VERSION ""

NS_ :

BS_:

BU_: XXX

BO_ 85 CID_QWMLCN: 8 XXX
 SG_ sig_wotptn : 40|1@1+ (1,0) [0|1] "" XXX
 SG_ sig_twcvod : 56|8@1+ (1,0) [0|255] "" XXX

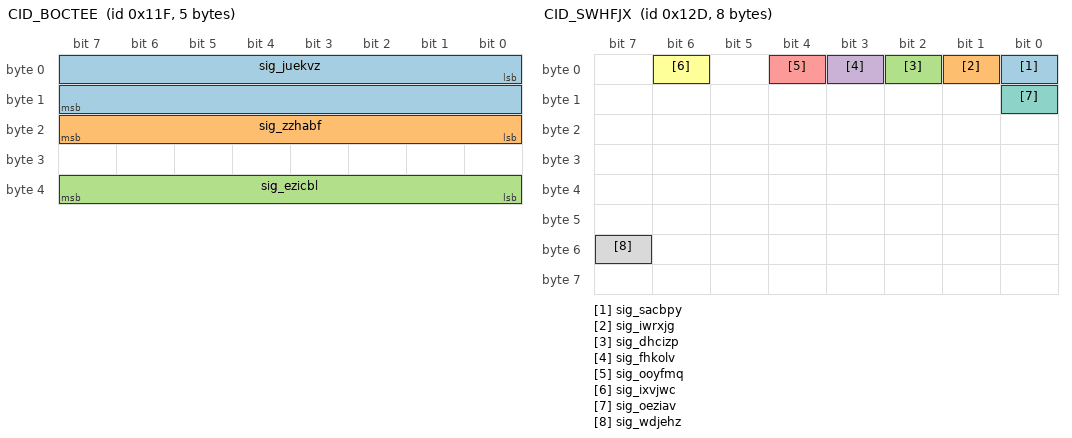
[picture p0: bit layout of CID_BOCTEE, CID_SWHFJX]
BO_ 287 CID_BOCTEE: 5 XXX
 SG_ sig_juekvz : 0|16@1- (0.1,0) [-450|450] "" XXX
 SG_ sig_zzhabf : 16|8@1+ (4,0) [0|1020] "" XXX
 SG_ sig_ezicbl : 32|8@1+ (1,0) [0|255] "" XXX

BO_ 289 CID_AZITHL: 8 XXX
 SG_ sig_vuvkgr : 0|12@1+ (1,0) [0|255] "" XXX

BO_ 301 CID_SWHFJX: 8 XXX
 SG_ sig_sacbpy : 0|1@0+ (1,0) [0|1] "" XXX
 SG_ sig_iwrxjg : 1|1@0+ (1,0) [0|1] "" XXX
 SG_ sig_dhcizp : 2|1@0+ (1,0) [0|1] "" XXX
 SG_ sig_fhkolv : 3|1@0+ (1,0) [0|1] "" XXX
 SG_ sig_ooyfmq : 4|1@0+ (1,0) [0|1] "" XXX
 SG_ sig_ixvjwc : 6|1@0+ (1,0) [0|1] "" XXX
 SG_ sig_oeziav : 8|1@0+ (1,0) [0|1] "" XXX
 SG_ sig_wdjehz : 55|1@0+ (1,0) [0|1] "" XXX

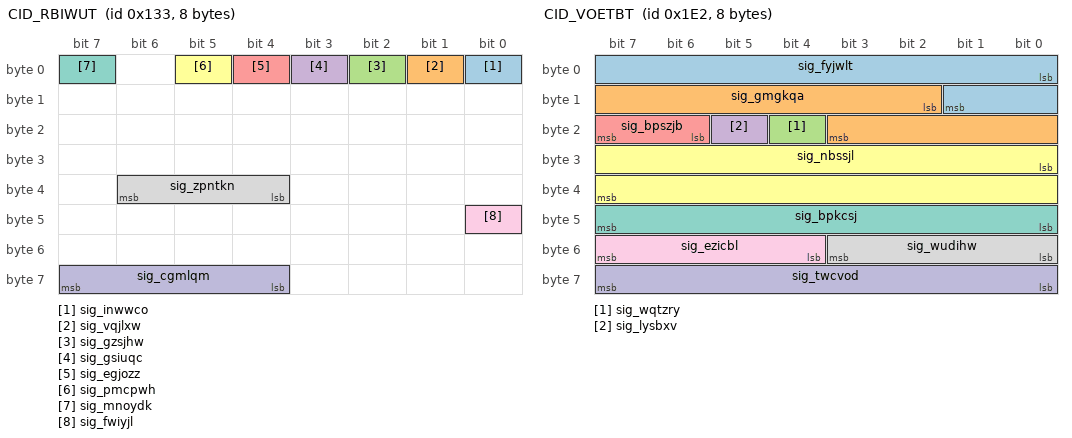
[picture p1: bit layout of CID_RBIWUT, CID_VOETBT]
BO_ 307 CID_RBIWUT: 8 XXX
 SG_ sig_inwwco : 0|1@0+ (1,0) [0|1] "" XXX
 SG_ sig_vqjlxw : 1|1@1+ (1,0) [0|1] "" XXX
 SG_ sig_gzsjhw : 2|1@1+ (1,0) [0|1] "" XXX
 SG_ sig_gsiuqc : 3|1@1+ (1,0) [0|1] "" XXX
 SG_ sig_egjozz : 4|1@0+ (1,0) [0|1] "" XXX
 SG_ sig_pmcpwh : 5|1@0+ (1,0) [0|1] "" XXX
 SG_ sig_mnoydk : 7|1@0+ (1,0) [0|1] "" XXX
 SG_ sig_zpntkn : 36|3@1+ (1,0) [0|7] "" XXX
 SG_ sig_fwiyjl : 40|1@0+ (1,0) [0|1] "" XXX
 SG_ sig_cgmlqm : 63|4@0+ (1,0) [0|15] "" XXX

BO_ 482 CID_VOETBT: 8 XXX
 SG_ sig_fyjwlt : 0|10@1- (0.01,0) [0|5] "" XXX
 SG_ sig_gmgkqa : 10|10@1- (0.01,0) [-5|0] "" XXX
 SG_ sig_wqtzry : 20|1@0+ (1,0) [0|1] "" XXX
 SG_ sig_lysbxv : 21|1@0+ (1,0) [0|1] "" XXX
 SG_ sig_bpszjb : 22|2@1+ (1,0) [0|1] "" XXX
 SG_ sig_nbssjl : 24|16@1- (0.1,0) [-780|779.9] "" XXX
 SG_ sig_bpkcsj : 47|8@0+ (1,0) [0|255] "" XXX
 SG_ sig_wudihw : 48|4@1+ (1,0) [0|15] "" XXX
 SG_ sig_ezicbl : 52|4@1+ (1,0) [0|15] "" XXX
 SG_ sig_twcvod : 56|8@1+ (1,0) [0|255] "" XXX

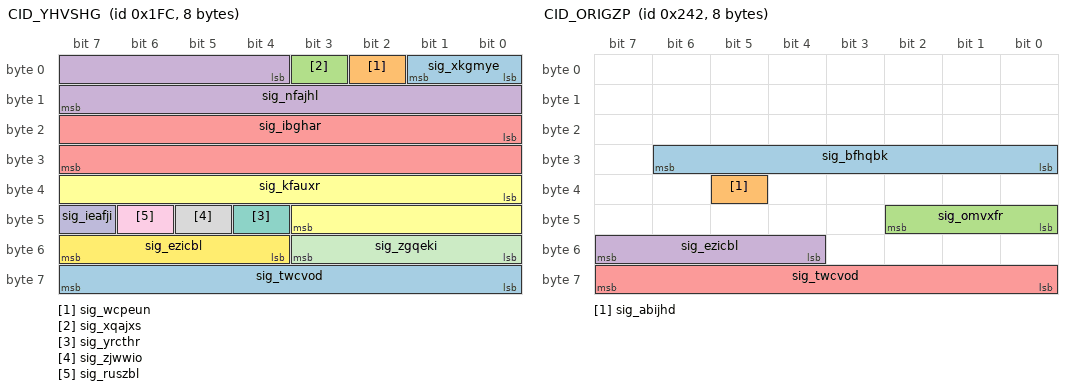
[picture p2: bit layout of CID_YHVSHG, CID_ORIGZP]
BO_ 508 CID_YHVSHG: 8 XXX
 SG_ sig_xkgmye : 0|2@1+ (1,0) [0|1] "" XXX
 SG_ sig_wcpeun : 2|1@1+ (1,0) [0|1] "" XXX
 SG_ sig_xqajxs : 3|1@0+ (1,0) [0|1] "" XXX
 SG_ sig_nfajhl : 4|12@1- (1,0) [-2048|2047] "" XXX
 SG_ sig_ibghar : 16|16@1- (0.1,0) [-780|779.9] "Deg" XXX
 SG_ sig_kfauxr : 32|12@1- (1,0) [0|63] "" XXX
 SG_ sig_yrcthr : 44|1@0+ (1,0) [0|1] "" XXX
 SG_ sig_zjwwio : 45|1@1+ (1,0) [0|255] "" XXX
 SG_ sig_ruszbl : 46|1@1+ (1,0) [0|1] "" XXX
 SG_ sig_ieafji : 47|1@0+ (1,0) [0|3] "" XXX
 SG_ sig_zgqeki : 48|4@1+ (1,0) [0|15] "" XXX
 SG_ sig_ezicbl : 52|4@1+ (1,0) [0|15] "" XXX
 SG_ sig_twcvod : 56|8@1+ (1,0) [0|255] "" XXX

BO_ 578 CID_ORIGZP: 8 XXX
 SG_ sig_bfhqbk : 30|7@0+ (1,0) [0|127] "" XXX
 SG_ sig_abijhd : 37|1@0+ (1,0) [0|1] "" XXX
 SG_ sig_omvxfr : 40|3@1+ (1,0) [0|7] "" XXX
 SG_ sig_ezicbl : 55|4@0+ (1,0) [0|15] "" XXX
 SG_ sig_twcvod : 56|8@1+ (1,0) [0|255] "" XXX

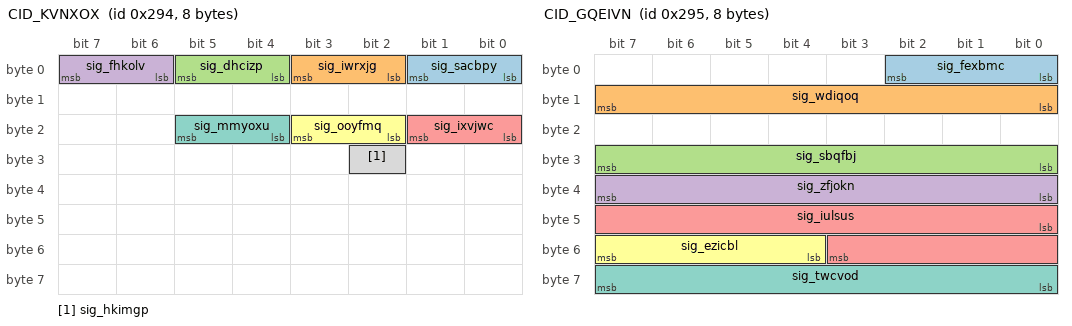
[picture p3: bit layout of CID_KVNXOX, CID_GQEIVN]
BO_ 660 CID_KVNXOX: 8 XXX
 SG_ sig_sacbpy : 1|2@0+ (1,0) [0|3] "" XXX
 SG_ sig_iwrxjg : 3|2@0+ (1,0) [0|3] "" XXX
 SG_ sig_dhcizp : 5|2@0+ (1,0) [0|3] "" XXX
 SG_ sig_fhkolv : 7|2@0+ (1,0) [0|3] "" XXX
 SG_ sig_ixvjwc : 17|2@0+ (1,0) [0|3] "" XXX
 SG_ sig_ooyfmq : 19|2@0+ (1,0) [0|3] "" XXX
 SG_ sig_mmyoxu : 21|2@0+ (1,0) [0|3] "" XXX
 SG_ sig_hkimgp : 26|1@0+ (1,0) [0|1] "" XXX

BO_ 661 CID_GQEIVN: 8 XXX
 SG_ sig_fexbmc : 2|3@0+ (1,0) [0|7] "" XXX
 SG_ sig_wdiqoq : 15|8@0+ (1,0) [0|255] "" XXX
 SG_ sig_sbqfbj : 31|8@0+ (1,0) [0|255] "" XXX
 SG_ sig_zfjokn : 32|8@1+ (1,0) [0|255] "" XXX
 SG_ sig_iulsus : 40|12@1+ (1,0) [0|255] "" XXX
 SG_ sig_ezicbl : 52|4@1+ (1,0) [0|15] "" XXX
 SG_ sig_twcvod : 63|8@0+ (1,0) [0|255] "" XXX

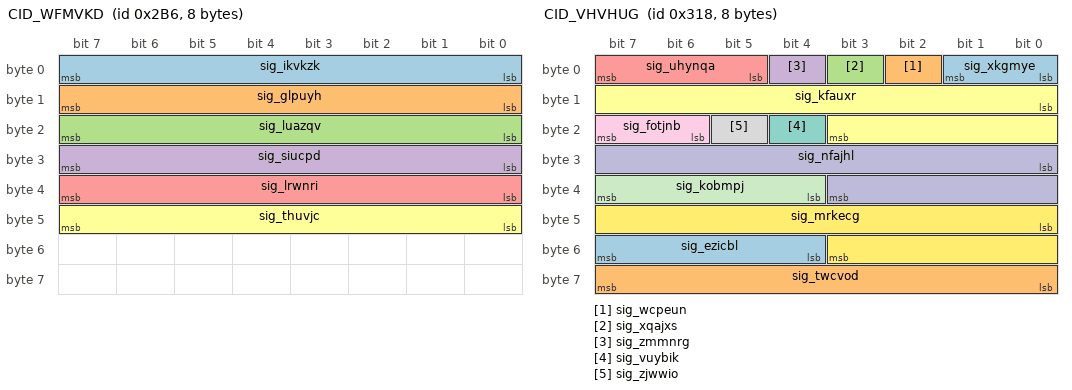
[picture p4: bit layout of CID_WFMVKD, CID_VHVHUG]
BO_ 694 CID_WFMVKD: 8 XXX
 SG_ sig_ikvkzk : 7|8@0+ (1,0) [0|255] "" XXX
 SG_ sig_glpuyh : 15|8@0+ (1,0) [0|255] "" XXX
 SG_ sig_luazqv : 23|8@0+ (1,0) [0|255] "" XXX
 SG_ sig_siucpd : 31|8@0+ (1,0) [0|255] "" XXX
 SG_ sig_lrwnri : 39|8@0+ (1,0) [0|255] "" XXX
 SG_ sig_thuvjc : 47|8@0+ (1,0) [0|255] "" XXX

BO_ 790 CID_ZNRPBW: 8 XXX
 SG_ sig_obblly : 3|4@0+ (1,0) [0|1] "" XXX
 SG_ sig_dymwgh : 4|2@1+ (1,0) [0|3] "" XXX
 SG_ sig_dqeexy : 6|2@1+ (1,0) [0|3] "" XXX
 SG_ sig_mzolpg : 8|2@1+ (1,0) [0|3] "" XXX
 SG_ sig_cwoikn : 10|1@1+ (1,0) [0|1] "" XXX
 SG_ sig_hmziyn : 11|4@1+ (1,0) [0|1] "" XXX
 SG_ sig_jwsmhk : 15|1@0+ (1,0) [0|1] "" XXX
 SG_ sig_nbssjl : 16|11@1- (1,0) [-1024|1023] "" XXX
 SG_ sig_wqtzry : 27|1@1+ (1,0) [0|1] "" XXX
 SG_ sig_lysbxv : 28|1@1+ (1,0) [0|3] "" XXX
 SG_ sig_eiozmu : 29|1@0+ (1,0) [0|1] "" XXX
 SG_ sig_hbujry : 30|1@0+ (1,0) [0|1] "" XXX
 SG_ sig_rdiowz : 31|1@0+ (1,0) [0|1] "" XXX
 SG_ sig_uvgzko : 32|2@1+ (1,0) [0|3] "" XXX
 SG_ sig_jesvlj : 34|2@1+ (1,0) [0|3] "" XXX
 SG_ sig_mxucei : 36|4@1+ (1,0) [0|3] "" XXX
 SG_ sig_zrcvfm : 40|8@1+ (5,-5) [-5|1270] "" XXX
 SG_ sig_cyqoup : 49|2@0+ (1,0) [0|3] "" XXX
 SG_ sig_ptdgev : 51|2@0+ (1,0) [0|3] "" XXX
 SG_ sig_ezicbl : 52|4@1+ (1,0) [0|15] "" XXX
 SG_ sig_twcvod : 56|8@1+ (1,0) [0|15] "" XXX

BO_ 792 CID_VHVHUG: 8 XXX
 SG_ sig_xkgmye : 0|2@1+ (1,0) [0|1] "" XXX
 SG_ sig_wcpeun : 2|1@1+ (1,0) [0|1] "" XXX
 SG_ sig_xqajxs : 3|1@1+ (1,0) [0|1] "" XXX
 SG_ sig_zmmnrg : 4|1@1+ (1,0) [0|1] "" XXX
 SG_ sig_uhynqa : 5|3@1+ (1,0) [0|1] "" XXX
 SG_ sig_kfauxr : 8|12@1- (1,0) [-2048|2047] "" XXX
 SG_ sig_vuybik : 20|1@1+ (1,0) [0|1] "" XXX
 SG_ sig_zjwwio : 21|1@1+ (1,0) [0|1] "" XXX
 SG_ sig_fotjnb : 22|2@1+ (1,0) [0|15] "" XXX
 SG_ sig_nfajhl : 24|12@1- (1,0) [-2048|2047] "" XXX
 SG_ sig_kobmpj : 36|4@1+ (1,0) [0|15] "" XXX
 SG_ sig_mrkecg : 40|12@1+ (1,0) [0|4095] "" XXX
 SG_ sig_ezicbl : 52|4@1+ (1,0) [0|15] "" XXX
 SG_ sig_twcvod : 56|8@1+ (1,0) [0|255] "" XXX

BO_ 813 CID_UCGIXE: 8 XXX
 SG_ sig_zydmvl : 0|9@1+ (0.5,0) [0|255.5] "" XXX
 SG_ sig_cajiau : 9|1@1+ (1,0) [0|1] "" XXX
 SG_ sig_xrmdnn : 10|3@1+ (1,0) [0|7] "" XXX
 SG_ sig_ltdgjd : 13|3@1+ (1,0) [0|7] "" XXX
 SG_ sig_pjzswe : 16|1@1+ (1,0) [0|1] "" XXX
 SG_ sig_rezzbs : 17|1@1+ (1,0) [0|1] "" XXX
 SG_ sig_xqajxs : 18|1@1+ (1,0) [0|1] "" XXX
 SG_ sig_retfwz : 19|3@1+ (1,0) [0|1] "" XXX
 SG_ sig_uelmyj : 22|1@0+ (1,0) [0|1] "" XXX
 SG_ sig_cshazi : 23|1@0+ (1,0) [0|1] "" XXX
 SG_ sig_mzolpg : 24|1@1+ (1,0) [0|1] "" XXX
 SG_ sig_iouldm : 25|7@1+ (1,0) [0|127] "" XXX
 SG_ sig_xvrvpx : 32|4@1+ (1,0) [0|15] "" XXX
 SG_ sig_ptorxn : 36|12@1+ (1,0) [0|4095] "" XXX
 SG_ sig_ezicbl : 48|4@1+ (1,0) [0|15] "" XXX
 SG_ sig_qnwojk : 55|4@0+ (1,0) [0|15] "" XXX
 SG_ sig_twcvod : 56|8@1+ (1,0) [0|255] "" XXX

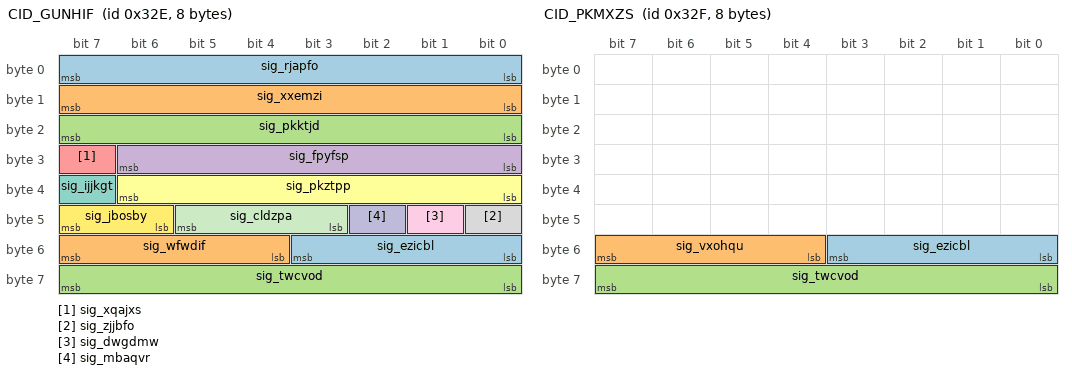
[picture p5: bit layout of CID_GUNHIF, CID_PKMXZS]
BO_ 814 CID_GUNHIF: 8 XXX
 SG_ sig_rjapfo : 0|8@1+ (0.05,-5) [-100|155] "" XXX
 SG_ sig_xxemzi : 8|8@1+ (0.05,-5) [0|1.26] "" XXX
 SG_ sig_pkktjd : 16|8@1+ (0.05,-5) [0|1.26] "" XXX
 SG_ sig_fpyfsp : 24|7@1+ (0.2,0) [0|12.7] "" XXX
 SG_ sig_xqajxs : 31|1@0+ (1,0) [0|1] "" XXX
 SG_ sig_pkztpp : 32|7@1+ (0.2,-16) [0|12.7] "" XXX
 SG_ sig_ijjkgt : 39|1@0+ (1,0) [0|1] "" XXX
 SG_ sig_zjjbfo : 40|1@0+ (1,0) [0|1] "" XXX
 SG_ sig_dwgdmw : 41|1@0+ (1,0) [0|1] "" XXX
 SG_ sig_mbaqvr : 42|1@1+ (1,0) [0|3] "" XXX
 SG_ sig_cldzpa : 45|3@0+ (1,0) [0|1] "" XXX
 SG_ sig_jbosby : 46|2@1+ (1,0) [0|3] "" XXX
 SG_ sig_ezicbl : 48|4@1+ (1,0) [0|15] "" XXX
 SG_ sig_wfwdif : 55|4@0+ (1,0) [0|15] "" XXX
 SG_ sig_twcvod : 56|8@1+ (1,0) [0|255] "" XXX

BO_ 815 CID_PKMXZS: 8 XXX
 SG_ sig_ezicbl : 48|4@1+ (1,0) [0|15] "" XXX
 SG_ sig_vxohqu : 55|4@0+ (1,0) [0|15] "" XXX
 SG_ sig_twcvod : 56|8@1+ (1,0) [0|255] "" XXX

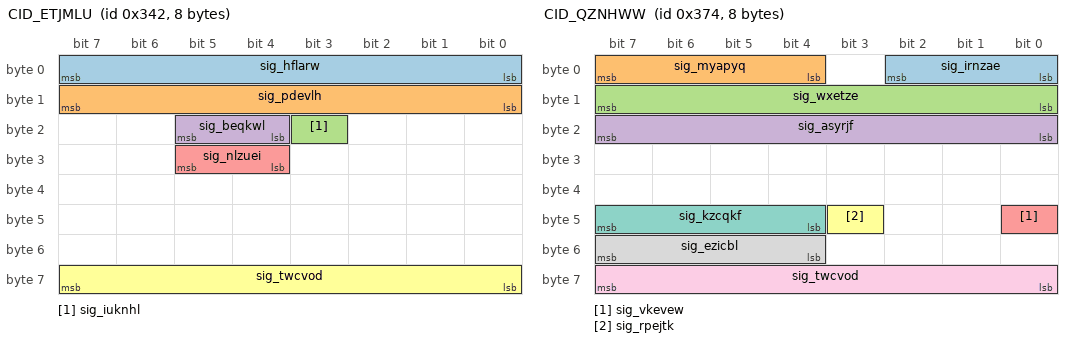
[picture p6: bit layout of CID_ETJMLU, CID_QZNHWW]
BO_ 834 CID_ETJMLU: 8 XXX
 SG_ sig_hflarw : 0|8@1+ (0.01,0) [0|2.55] "" XXX
 SG_ sig_pdevlh : 8|8@1+ (0.01,0) [0|2.55] "" XXX
 SG_ sig_iuknhl : 19|1@1+ (1,0) [0|1] "" XXX
 SG_ sig_beqkwl : 20|2@1+ (1,0) [0|255] "" XXX
 SG_ sig_nlzuei : 28|2@1+ (1,0) [0|1] "" XXX
 SG_ sig_twcvod : 56|8@1+ (1,0) [0|255] "" XXX

BO_ 884 CID_QZNHWW: 8 MRR
 SG_ sig_irnzae : 2|3@0+ (1,0) [0|3] "" MRR
 SG_ sig_myapyq : 7|4@0+ (1,0) [0|15] "" MRR
 SG_ sig_wxetze : 15|8@0+ (0.1,-12) [0|255] "" MRR
 SG_ sig_asyrjf : 23|8@0+ (1,-100) [0|255] "" MRR
 SG_ sig_vkevew : 40|1@0+ (1,0) [0|3] "" MRR
 SG_ sig_rpejtk : 43|1@0+ (1,0) [0|1] "" XXX
 SG_ sig_kzcqkf : 44|4@1+ (1,0) [0|15] "" XXX
 SG_ sig_ezicbl : 52|4@1+ (1,0) [0|15] "" MRR
 SG_ sig_twcvod : 56|8@1+ (1,0) [0|255] "" MRR

BO_ 944 CID_ZPZWLF: 8 XXX
 SG_ sig_nthylz : 1|2@0+ (1,0) [0|3] "" XXX
 SG_ sig_gagnpk : 2|1@0+ (1,0) [0|1] "" XXX
 SG_ sig_pjnood : 4|2@0+ (1,0) [0|3] "" XXX
 SG_ sig_wsvqgl : 5|1@0+ (1,0) [0|1] "" XXX
 SG_ sig_vagygw : 6|1@0+ (1,0) [0|1] "" XXX
 SG_ sig_feuvwv : 7|1@0+ (1,0) [0|1] "" XXX
 SG_ sig_ojcjkd : 8|1@0+ (1,0) [0|1] "" XXX
 SG_ sig_yduvat : 11|3@0+ (1,0) [0|7] "" XXX
 SG_ sig_kdzzim : 12|1@0+ (1,0) [0|1] "" XXX
 SG_ sig_xmyiyl : 14|2@0+ (1,0) [0|3] "" XXX
 SG_ sig_ejuphi : 15|1@0+ (1,0) [0|1] "" XXX
 SG_ sig_jikbyl : 16|1@0+ (1,0) [0|1] "" XXX
 SG_ sig_iqsonn : 18|2@0+ (1,0) [0|3] "" XXX
 SG_ sig_pkednv : 19|1@0+ (1,0) [0|1] "" XXX
 SG_ sig_hvyosh : 23|4@0+ (1,0) [0|15] "" XXX
 SG_ sig_ihubio : 24|28@1+ (1,0) [0|268435455] "" XXX
 SG_ sig_ezicbl : 52|4@1+ (1,0) [0|15] "" XXX
 SG_ sig_twcvod : 56|8@1+ (1,0) [0|255] "" XXX

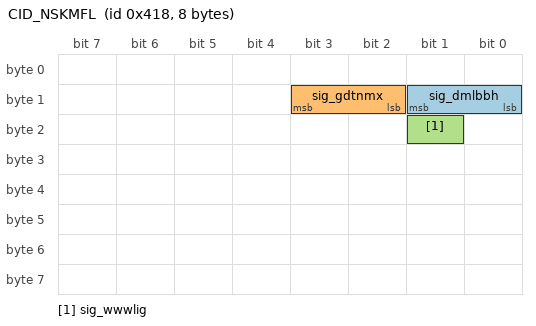
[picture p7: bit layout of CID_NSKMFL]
BO_ 1048 CID_NSKMFL: 8 XXX
 SG_ sig_dmlbbh : 9|2@0+ (1,0) [0|1] "" XXX
 SG_ sig_gdtnmx : 11|2@0+ (1,0) [0|1] "" XXX
 SG_ sig_wwwlig : 17|1@0+ (1,0) [0|1] "" XXX

VAL_ 578 sig_omvxfr 4 "D" 2 "R" 3 "N" 1 "P";
VAL_ 790 sig_obblly 11 "AutoFullBeamActive" 2 "AutoFullBeamInactive";
VAL_ 790 sig_dymwgh 0 "GRAY" 1 "GREEN" 2 "YELLOW" 3 "RED";
VAL_ 790 sig_dqeexy 3 "ALARM_AND_LKA" 2 "LKA" 1 "ALARM" 0 "DISABLE";
VAL_ 790 sig_jesvlj 0 "GRAY" 1 "GREEN" 2 "YELLOW" 3 "RED";
VAL_ 790 sig_cyqoup 0 "VIBRATION" 1 "AUDIO" 2 "AUDIO_AND_VIBRATION";
VAL_ 792 sig_xkgmye 0 "NotReady" 1 "Ready" 2 "Active" 3 "TemporaryFail";
VAL_ 813 sig_xrmdnn 4 "4BAR" 3 "3BAR" 2 "2BAR" 1 "1BAR";
VAL_ 813 sig_retfwz 0 "OFF" 2 "ACC_ON" 3 "ACC_ACTIVE" 5 "FORCE_ACCEL" 7 "ERROR";
VAL_ 813 sig_iouldm 36 "ACC_ERROR" 22 "OVERRIDE" 12 "ENGAGE" 8 "DISENGAGE" 20 "ACC_ON" 32 "ACC_OFF" 48 "CHECK_GEAR_D" 16 "FORCE_ACCEL" 0 "NONE";
VAL_ 814 sig_cldzpa 0 "Off" 1 "Passive" 2 "StandBy" 3 "ActiveControl" 4 "BrakeOnly" 5 "Override" 6 "Standstill" 7 "Failure";
VAL_ 814 sig_jbosby 0 "Softoff" 1 "Fastoff" 2 "Immediateoff" 3 "Initial";
VAL_ 834 sig_beqkwl 2 "SPORT" 1 "ECO" 0 "SNOW";
VAL_ 834 sig_nlzuei 3 "HEV" 2 "FORCE_EV" 1 "EV";
VAL_ 944 sig_pjnood 0 "NOTPRESSED" 1 "DOWN_SETSPEED" 3 "UP_RESETSPEED";
